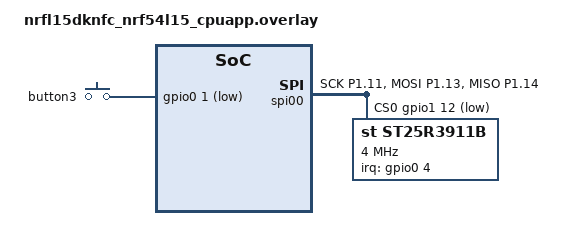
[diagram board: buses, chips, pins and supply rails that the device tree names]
// To get started, press Ctrl+Space to bring up the completion menu and view the available nodes.

// You can also use the buttons in the sidebar to perform actions on nodes.
// Actions currently available include:

// * Enabling / disabling the node
// * Adding the bus to a bus
// * Removing the node
// * Connecting ADC channels

// For more help, browse the DeviceTree documentation at https: //docs.zephyrproject.org/latest/guides/dts/index.html
// You can also visit the nRF DeviceTree extension documentation at https: //docs.nordicsemi.com/bundle/nrf-connect-vscode/page/guides/ncs_configure_app.html#devicetree-support-in-the-extension
&spi00 {
	compatible = "nordic,nrf-spim";
	status = "okay";
	cs-gpios = <&gpio1 12 GPIO_ACTIVE_LOW>;

	pinctrl-0 = <&spi1_default_alt>;
	pinctrl-1 = <&spi1_sleep_alt>;
	pinctrl-names = "default", "sleep";
	st25r3911b@0 {
		compatible = "st,st25r3911b";
		reg = <0>;
		spi-max-frequency = <4000000>;
		irq-gpios = <&gpio0 4 GPIO_ACTIVE_HIGH>;
	};
};

&pinctrl {
	spi1_default_alt: spi1_default_alt {
		group1 {
			psels = <NRF_PSEL(SPIM_SCK, 1, 11)>,
			        <NRF_PSEL(SPIM_MOSI, 1, 13)>,
			        <NRF_PSEL(SPIM_MISO, 1, 14)>;
		};
	};

	spi1_sleep_alt: spi1_sleep_alt {
		group1 {
			psels = <NRF_PSEL(SPIM_SCK, 1, 11)>,
			        <NRF_PSEL(SPIM_MOSI, 1, 13)>,
			        <NRF_PSEL(SPIM_MISO, 1, 14)>;
			low-power-enable;
		};
	};

};
&button3 {
	gpios = <&gpio0 1 (GPIO_ACTIVE_LOW | GPIO_PULL_UP)>;
};
